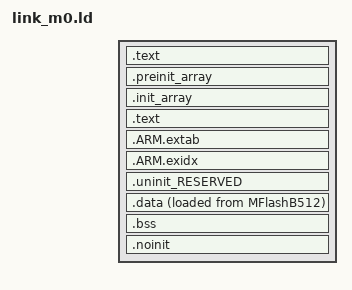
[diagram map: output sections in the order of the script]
INCLUDE mem.ld
INCLUDE libs.ld

ENTRY(Reset_Handler)

SECTIONS
{
    /* MAIN TEXT SECTION */
    .text : ALIGN(4)
    {
        FILL(0xff)
        __vectors_start__ = ABSOLUTE(.) ;
        KEEP(*(.isr_vector))
        KEEP(*(.isr_vendor_vector))

        /* Global Section Table */
        . = ALIGN(4) ;
        __section_table_start = .;
        __data_section_table = .;
        LONG(LOADADDR(.data));
        LONG(    ADDR(.data));
        LONG(  SIZEOF(.data));
        __data_section_table_end = .;
        __bss_section_table = .;
        LONG(    ADDR(.bss));
        LONG(  SIZEOF(.bss));
        __bss_section_table_end = .;
        __section_table_end = . ;
        /* End of Global Section Table */

        *(.after_vectors*)

        /* Code Read Protect data */
        . = 0x000002FC ;
        PROVIDE(__CRP_WORD_START__ = .) ;
        KEEP(*(.crp))
        PROVIDE(__CRP_WORD_END__ = .) ;
        ASSERT(!(__CRP_WORD_START__ == __CRP_WORD_END__), "Linker CRP Enabled, but no CRP_WORD provided within application");
        /* End of Code Read Protect */

    } >MFlashB512
    . = ALIGN(4);

   .preinit_array     :
   {
     PROVIDE_HIDDEN (__preinit_array_start = .);
     KEEP (*(.preinit_array*))
     PROVIDE_HIDDEN (__preinit_array_end = .);
   } >MFlashB512
   
   .init_array :
   {
     PROVIDE_HIDDEN (__init_array_start = .);
     KEEP (*(SORT(.init_array.*)))
     KEEP (*(.init_array*))
     PROVIDE_HIDDEN (__init_array_end = .);
   } >MFlashB512
  
    . = ALIGN(4);

    .text : ALIGN(4)
    {
         *(.text*)
        *(.rodata .rodata.* .constdata .constdata.*)
        . = ALIGN(4);

    } > MFlashB512

    /*
     * for exception handling/unwind - some Newlib functions (in common
     * with C++ and STDC++) use this.
     */
    .ARM.extab : ALIGN(4)
    {
       *(.ARM.extab* .gnu.linkonce.armextab.*)
    } > MFlashB512
    __exidx_start = .;

    .ARM.exidx : ALIGN(4)
    {
       *(.ARM.exidx* .gnu.linkonce.armexidx.*)
    } > MFlashB512
    __exidx_end = .;

    _etext = .;

    /* MAIN DATA SECTION */
    .uninit_RESERVED : ALIGN(4)
    {
        KEEP(*(.bss.$RESERVED*))
        . = ALIGN(4) ;
        _end_uninit_RESERVED = .;
    } > RamAHB32

   /* Main DATA section (RamAHB32) */
   .data : ALIGN(4)
   {
      FILL(0xff)
      _data = . ;
      *(vtable)
      *(.ramfunc*)
      *(.data*)
      . = ALIGN(4) ;
      _edata = . ;
   } > RamAHB32 AT>MFlashB512

    /* MAIN BSS SECTION */
    .bss : ALIGN(4)
    {
        _bss = .;
        *(.bss*)
        *(COMMON)
        . = ALIGN(4) ;
        _ebss = .;
        PROVIDE(end = .);
    } > RamAHB32

    /* DEFAULT NOINIT SECTION */
    .noinit (NOLOAD): ALIGN(4)
    {
        _noinit = .;
        *(.noinit*)
         . = ALIGN(4) ;
        _end_noinit = .;
    } > RamAHB32

    PROVIDE(_pvHeapStart = .);
    PROVIDE(_vStackTop = ORIGIN(RamAHB32) + LENGTH(RamAHB32));
    PROVIDE(__valid_user_code_checksum = 0 -
         (_vStackTop
         + (Reset_Handler + 1)
         + (NMI_Handler + 1)
         + (HardFault_Handler + 1)
         + (( DEFINED(MemManage_Handler) ? MemManage_Handler : 0 ) + 1)   /* MemManage_Handler may not be defined */
         + (( DEFINED(BusFault_Handler) ? BusFault_Handler : 0 ) + 1)     /* BusFault_Handler may not be defined */
         + (( DEFINED(UsageFault_Handler) ? UsageFault_Handler : 0 ) + 1) /* UsageFault_Handler may not be defined */
         ) );
}
